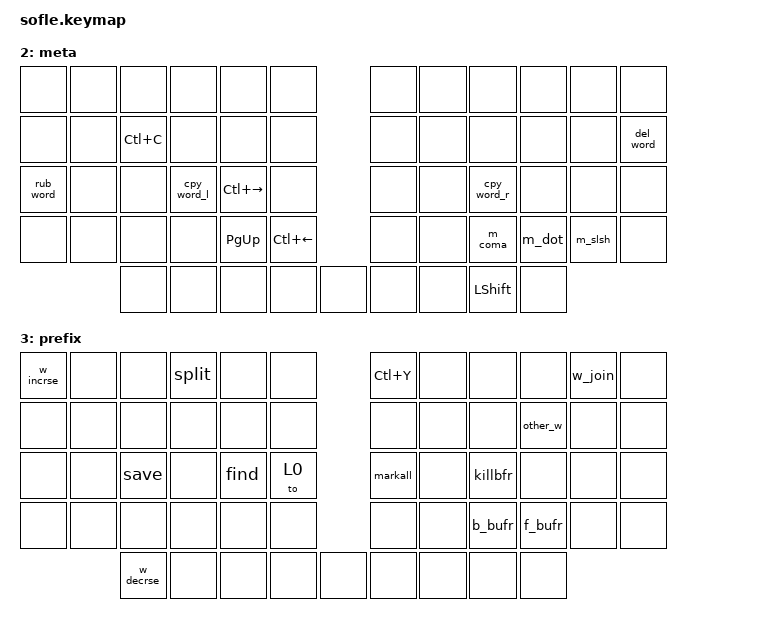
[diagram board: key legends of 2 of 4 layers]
/*
 * Copyright (c) 2020 The ZMK Contributors
 *
 * SPDX-License-Identifier: MIT
 */

#include <dt-bindings/led/led.h>
#include <behaviors.dtsi>
#include <dt-bindings/zmk/keys.h>

&spi3 {
    compatible = "nordic,nrf-spim";
    status = "okay";
    pinctrl-0 = <&spi3_default>;
    pinctrl-1 = <&spi3_sleep>;
    pinctrl-names = "default", "sleep";

    led_strip: ws2812@0 {
        compatible = "worldsemi,ws2812-spi";

        /* SPI */

        reg = <0>; /* ignored, but necessary for SPI bindings */
        spi-max-frequency = <4000000>;

        /* WS2812 */

        chain-length = <29>; /* arbitrary; change at will */
        spi-one-frame = <0x70>;
        spi-zero-frame = <0x40>;
        color-mapping = <LED_COLOR_ID_GREEN LED_COLOR_ID_RED LED_COLOR_ID_BLUE>;
    };
};

nice_view_spi: &spi0 {
    compatible = "nordic,nrf-spim";
    pinctrl-0 = <&spi0_default>;
    pinctrl-1 = <&spi0_sleep>;
    pinctrl-names = "default", "sleep";

    cs-gpios = <&pro_micro 0 GPIO_ACTIVE_HIGH>;
};

/ {
    chosen { zmk,underglow = &led_strip; };
};

/ {
    behaviors {
        m_dot: m_dot {
            compatible = "zmk,behavior-mod-morph";
            #binding-cells = <0>;
            bindings = <&kp F12>, <&kp LC(END)>;
            mods = <MOD_LSFT>;
        };
        m_coma: m_coma {
            compatible = "zmk,behavior-mod-morph";
            #binding-cells = <0>;
            bindings = <&kp LA(LEFT)>, <&kp LC(HOME)>;
            mods = <MOD_LSFT>;
        };
        m_slsh: m_slsh {
            compatible = "zmk,behavior-mod-morph";
            #binding-cells = <0>;
            bindings = <&kp LC(SPACE)>, <&kp LC(Y)>;
            mods = <MOD_LSFT>;
        };
    };

    macros {
        find: find {
            compatible = "zmk,behavior-macro";
            #binding-cells = <0>;
            bindings =
                <&macro_tap &kp LC(P)>,
                <&to 0>;
        };
        save: save {
            compatible = "zmk,behavior-macro";
            #binding-cells = <0>;
            bindings =
                <&macro_tap &kp LC(S)>,
                <&to 0>;
        };
        killbfr: killbfr {
            compatible = "zmk,behavior-macro";
            #binding-cells = <0>;
            bindings =
                <&macro_tap &kp LC(W)>,
                <&to 0>;
        };
        nextbfr: nextbfr {
            compatible = "zmk,behavior-macro";
            #binding-cells = <0>;
            bindings =
                <&macro_tap &kp LC(TAB)>,
                <&to 0>;
        };
        markall: markall {
            compatible = "zmk,behavior-macro";
            #binding-cells = <0>;
            bindings =
                <&macro_tap &kp LC(A)>,
                <&to 0>;
        };
        cpy_line_r: cpy_line_r {
            compatible = "zmk,behavior-macro";
            #binding-cells = <0>;
            bindings =
                <&macro_tap &kp LS(END)>,
                <&macro_tap &kp LC(C)>,
                <&macro_tap &kp LEFT>;
        };
        cpy_word_r: cpy_word_r {
            compatible = "zmk,behavior-macro";
            #binding-cells = <0>;
            bindings =
                <&macro_tap &kp LS(LC(RIGHT))>,
                <&macro_tap &kp LC(C)>,
                <&macro_tap &kp LEFT>;
        };
        del_line: del_line {
            compatible = "zmk,behavior-macro";
            #binding-cells = <0>;
            bindings =
                <&macro_tap &kp LS(END)>,
                <&macro_tap &kp DEL>;
        };
        del_word: del_word {
            compatible = "zmk,behavior-macro";
            #binding-cells = <0>;
            bindings =
                <&macro_tap &kp LS(LC(RIGHT))>,
                <&macro_tap &kp DEL>;
        };
        cpy_line_l: cpy_line_l {
            compatible = "zmk,behavior-macro";
            #binding-cells = <0>;
            bindings =
                <&macro_tap &kp LS(HOME)>,
                <&macro_tap &kp LC(C)>,
                <&macro_tap &kp RIGHT>;
        };
        cpy_word_l: cpy_word_l {
            compatible = "zmk,behavior-macro";
            #binding-cells = <0>;
            bindings =
                <&macro_tap &kp LS(LC(LEFT))>,
                <&macro_tap &kp LC(C)>,
                <&macro_tap &kp RIGHT>;
        };
        rub_line: rub_line {
            compatible = "zmk,behavior-macro";
            #binding-cells = <0>;
            bindings =
                <&macro_tap &kp LS(HOME)>,
                <&macro_tap &kp BSPC>;
        };
        rub_word: rub_word {
            compatible = "zmk,behavior-macro";
            #binding-cells = <0>;
            bindings =
                <&macro_tap &kp LS(LC(LEFT))>,
                <&macro_tap &kp BSPC>;
        };
        split: split {
            compatible = "zmk,behavior-macro";
            #binding-cells = <0>;
            bindings =
                <&macro_tap &kp LC(BSLH)>,
                <&macro_tap &kp LC(K)>,
                <&macro_tap &kp LC(Y)>,
                <&to 0>;
        };
        w_incrse: w_incrse {
            compatible = "zmk,behavior-macro";
            #binding-cells = <0>;
            bindings =
                <&macro_tap &kp LC(X)>,
                <&macro_tap &kp EQUAL>,
                <&to 0>;
        };
        w_decrse: w_decrse {
            compatible = "zmk,behavior-macro";
            #binding-cells = <0>;
            bindings =
                <&macro_tap &kp LC(X)>,
                <&macro_tap &kp MINUS>,
                <&to 0>;
        };
        other_w: other_w {
            compatible = "zmk,behavior-macro";
            #binding-cells = <0>;
            bindings =
                <&macro_tap &kp LC(K)>,
                <&macro_tap &kp LC(Y)>,
                <&to 0>;
        };
        w_join: w_join {
            compatible = "zmk,behavior-macro";
            #binding-cells = <0>;
            bindings =
                <&macro_tap &kp LC(X)>,
                <&macro_tap &kp N0>,
                <&to 0>;
        };
        f_bufr: f_bufr {
            compatible = "zmk,behavior-macro";
            #binding-cells = <0>;
            bindings =
                <&macro_tap &kp LC(PG_DN)>,
                <&to 0>;
        };
        b_bufr: b_bufr {
            compatible = "zmk,behavior-macro";
            #binding-cells = <0>;
            bindings =
                <&macro_tap &kp LC(PG_UP)>,
                <&to 0>;
        };
    };

    keymap {
        compatible = "zmk,keymap";

        default_layer {
            display-name = "Default";
            bindings = <
&kp EQUAL     &kp N1     &kp N2       &kp N3        &kp N4      &kp N5                      &kp N6     &kp N7     &kp N8      &kp N9    &kp N0      &kp GRAVE
&kp TAB       &kp Q      &kp W        &kp E         &kp R       &kp T                       &kp Y      &kp U      &kp I       &kp O     &kp P       &kp DEL
&kp BSPC      &kp A      &kp S        &kp D         &kp F       &kp G                       &kp H      &kp J      &kp K       &kp L     &kp SEMI    &kp RET
&kp ESC       &kp Z      &kp X        &kp C         &kp V       &kp B    &none     &none    &kp N      &kp M      &kp COMMA   &kp DOT   &kp SLASH   &kp BSLH
                         &kp MINUS    &kp LBKT      &mo 2       &mo 1    &none     &none    &kp SPACE  &kp LSHFT  &kp RBKT    &kp SQT
            >;

            sensor-bindings = <&inc_dec_kp C_VOL_UP C_VOL_DN &inc_dec_kp PG_UP PG_DN>;
        };
control {
            display-name = "control";
            bindings = <
&kp LC(EQUAL) &none      &none          &none        &none        &none                      &none      &none      &none         &none        &none         &none
&none         &none      &kp LC(X)      &kp END      &kp LS(F3)   &none                      &kp LC(V)  &none      &none         &none        &kp UP        &del_line
&rub_line     &kp HOME   &kp LC(F)      &cpy_line_l  &kp RIGHT    &none                      &none      &none      &cpy_line_r   &kp LC(L)    &kp LC(GRAVE) &none
&kp LC(B)     &none      &to 3          &none        &kp PG_DN    &kp LEFT    &none &none    &kp DOWN   &none      &kp LC(DOT)   &kp LC(F12)  &kp LC(Z)     &kp LC(J)
                         &kp LC(MINUS)  &none        &none        &none       &none &none    &none      &kp LSHFT  &none
            >;
        };
        meta {
            display-name = "meta";
            bindings = <
&none         &none    &none       &none        &none           &none                       &none     &none      &none        &none      &none        &none
&none         &none    &kp LC(C)   &none        &none           &none                       &none     &none      &none        &none      &none        &del_word
&rub_word     &none    &none       &cpy_word_l  &kp LC(RIGHT)   &none                       &none     &none      &cpy_word_r  &none      &none        &none
&none         &none    &none       &none        &kp PG_UP       &kp LC(LEFT)                &none     &none      &m_coma      &m_dot     &m_slsh      &none
                       &none       &none        &none           &none        &none &none    &none     &kp LSHFT  &none
            >;
        };
        prefix {
            display-name = "prefix";
            bindings = <
&w_incrse    &none       &none         &split      &none       &none                       &kp LC(Y)    &none      &none        &none       &w_join     &none
&none        &none       &none         &none       &none       &none                       &none        &none      &none        &other_w    &none      &none
&none        &none       &save         &none       &find       &to 0                       &markall     &none      &killbfr     &none       &none      &none
&none        &none       &none         &none       &none       &none                       &none        &none      &b_bufr      &f_bufr     &none      &none
                        &w_decrse      &none       &none       &none        &none &none    &none        &none      &none
            >;
        };
    };
};
